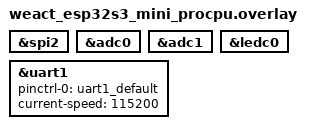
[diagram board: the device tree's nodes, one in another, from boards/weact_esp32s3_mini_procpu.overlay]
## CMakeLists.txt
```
cmake_minimum_required(VERSION 3.28.0)
find_package(Zephyr REQUIRED HINTS $ENV{ZEPHYR_BASE})
project(esp32s3_testbench)
target_sources(app PRIVATE
    src/main.c
    src/shell_cmds.c
    src/gpio_handler.c
    src/adc_handler.c
    src/pwm_handler.c
    src/spi_handler.c
    src/uart_handler.c
)
target_include_directories(app PRIVATE ${CMAKE_CURRENT_SOURCE_DIR}/inc)
```

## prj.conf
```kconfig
CONFIG_GPIO=y
CONFIG_SERIAL=y
CONFIG_CONSOLE=y
CONFIG_PRINTK=y
CONFIG_LOG=y
CONFIG_LOG_DEFAULT_LEVEL=3

# Zephyr shell (command interface over USB Serial/JTAG)
CONFIG_SHELL=y
CONFIG_SHELL_BACKEND_SERIAL=y
CONFIG_SHELL_PROMPT_UART="tb:~$ "

# Peripherals
CONFIG_ADC=y
CONFIG_PWM=y
CONFIG_SPI=y
```

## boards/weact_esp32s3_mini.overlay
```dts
/ {
    aliases {
        /* Logical names used by the command protocol */
    };
};

&gpio0 {
    status = "okay";
};
```

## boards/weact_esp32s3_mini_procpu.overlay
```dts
/* Enable peripherals used by the testbench */
&spi2 {
    status = "okay";
};

&adc0 {
    status = "okay";
};

&adc1 {
    status = "okay";
};

&ledc0 {
    status = "okay";
};

&uart1 {
    status = "okay";
    pinctrl-0 = <&uart1_default>;
    pinctrl-names = "default";
    current-speed = <115200>;
};
```

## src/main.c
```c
/*
 * Copyright (c) 2026 ITI Zephyr Playground
 * SPDX-License-Identifier: Apache-2.0
 */

#include <zephyr/kernel.h>
#include <zephyr/sys/printk.h>

int main(void)
{
    printk("ESP32-S3 Testbench ready (shell on USB Serial/JTAG)\r\n");
    while (1) {
        k_msleep(1000);
    }
    return 0;
}
```

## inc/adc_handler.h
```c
#ifndef ADC_HANDLER_H
#define ADC_HANDLER_H
int adc_handler_read(int channel, int *value);
#endif
```

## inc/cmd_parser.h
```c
#ifndef CMD_PARSER_H
#define CMD_PARSER_H

void cmd_parser_init(void);
void cmd_parser_process(void);

#endif
```

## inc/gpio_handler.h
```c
#ifndef GPIO_HANDLER_H
#define GPIO_HANDLER_H

int gpio_handler_config(int pin, int is_out);
int gpio_handler_set(int pin, int value);
int gpio_handler_get(int pin, int *value);

#endif
```

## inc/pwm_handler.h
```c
#ifndef PWM_HANDLER_H
#define PWM_HANDLER_H
int pwm_handler_set(int channel, int duty_percent);
#endif
```

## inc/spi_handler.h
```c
#ifndef SPI_HANDLER_H
#define SPI_HANDLER_H
int spi_handler_transfer(const unsigned char *tx, unsigned char *rx, size_t len);
#endif
```

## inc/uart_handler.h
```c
#ifndef UART_HANDLER_H
#define UART_HANDLER_H

int uart_handler_send(const char *text);
int uart_handler_recv(char *buf, size_t bufsize);

#endif
```

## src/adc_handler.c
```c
#include <zephyr/kernel.h>
#include <zephyr/device.h>
#include <zephyr/drivers/adc.h>

#include "adc_handler.h"

static const struct device *const adc_dev = DEVICE_DT_GET(DT_NODELABEL(adc0));

int adc_handler_read(int channel, int *value)
{
    if (!device_is_ready(adc_dev)) {
        return -1;
    }

    struct adc_channel_cfg cfg = {
        .gain = ADC_GAIN_1,
        .reference = ADC_REF_INTERNAL,
        .acquisition_time = ADC_ACQ_TIME_DEFAULT,
        .channel_id = channel,
    };

    int err = adc_channel_setup(adc_dev, &cfg);
    if (err < 0) {
        return err;
    }

    int16_t buf = 0;
    struct adc_sequence seq = {
        .channels = BIT(channel),
        .buffer = &buf,
        .buffer_size = sizeof(buf),
        .resolution = 12,
    };

    err = adc_read(adc_dev, &seq);
    if (err < 0) {
        return err;
    }

    *value = buf;
    return 0;
}
```

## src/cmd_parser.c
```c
#include <zephyr/kernel.h>
#include <zephyr/device.h>
#include <zephyr/drivers/uart.h>
#include <string.h>
#include <stdlib.h>
#include <stdio.h>

#include "cmd_parser.h"
#include "gpio_handler.h"
#include "adc_handler.h"
#include "pwm_handler.h"
#include "spi_handler.h"

static const struct device *const uart_dev = DEVICE_DT_GET(DT_CHOSEN(zephyr_console));

static char line_buf[128];
static size_t line_len = 0;

static void uart_send(const char *s)
{
    while (*s) {
        uart_poll_out(uart_dev, *s++);
    }
    uart_poll_out(uart_dev, '\r');
    uart_poll_out(uart_dev, '\n');
}

static void handle_line(char *line)
{
    char cmd[16] = {0}, a[16] = {0}, b[16] = {0};
    int n = sscanf(line, "%15s %15s %15s", cmd, a, b);

    if (!strcmp(line, "ping")) { uart_send("PONG"); return; }
    if (!strcmp(line, "help")) {
        uart_send("Commands: ping, help, gpio config/set/get, adc read <ch>, pwm set <ch> <duty>, spi xfer <hex...>");
        return;
    }

    if (!strcmp(cmd, "gpio")) {
        if (!strcmp(a, "config") ) {
            int pin; char mode[8];
            if (sscanf(line, "gpio config %d %7s", &pin, mode) == 2) {
                int r = gpio_handler_config(pin, !strcmp(mode, "out"));
                uart_send(r == 0 ? "OK" : "ERR 2");
                return;
            }
        }
        if (!strcmp(a, "set")) {
            int pin, val;
            if (sscanf(line, "gpio set %d %d", &pin, &val) == 2) {
                int r = gpio_handler_set(pin, val);
                uart_send(r == 0 ? "OK" : "ERR 2");
                return;
            }
        }
        if (!strcmp(a, "get")) {
            int pin;
            if (sscanf(line, "gpio get %d", &pin) == 1) {
                int v = 0;
                int r = gpio_handler_get(pin, &v);
                if (r == 0) {
                    char resp[32];
                    snprintf(resp, sizeof(resp), "VAL %d", v);
                    uart_send(resp);
                } else {
                    uart_send("ERR 2");
                }
                return;
            }
        }
    }

    if (!strcmp(cmd, "adc")) {
        if (!strcmp(a, "read")) {
            int ch;
            if (sscanf(line, "adc read %d", &ch) == 1) {
                int v = 0;
                int r = adc_handler_read(ch, &v);
                if (r == 0) {
                    char resp[32];
                    snprintf(resp, sizeof(resp), "VAL %d", v);
                    uart_send(resp);
                } else {
                    uart_send("ERR 2");
                }
                return;
            }
        }
    }

    if (!strcmp(cmd, "pwm")) {
        if (!strcmp(a, "set")) {
            int ch, duty;
            if (sscanf(line, "pwm set %d %d", &ch, &duty) == 2) {
                int r = pwm_handler_set(ch, duty);
                uart_send(r == 0 ? "OK" : "ERR 2");
                return;
            }
        }
    }

    if (!strcmp(cmd, "spi")) {
        if (!strcmp(a, "xfer")) {
            /* parse hex bytes after "spi xfer" */
            unsigned char tx[16], rx[16];
            size_t len = 0;
            char *p = line + strlen("spi xfer");
            while (*p && len < sizeof(tx)) {
                while (*p == ' ') p++;
                if (!*p) break;
                unsigned int byte;
                if (sscanf(p, "%2x", &byte) == 1) {
                    tx[len] = (unsigned char)byte;
                    rx[len] = 0;
                    len++;
                    p += 2;
                } else {
                    break;
                }
            }
            if (len > 0) {
                int r = spi_handler_transfer(tx, rx, len);
                if (r == 0) {
                    char resp[64];
                    size_t off = 0;
                    off += snprintf(resp + off, sizeof(resp) - off, "RX");
                    for (size_t i = 0; i < len; i++) {
                        off += snprintf(resp + off, sizeof(resp) - off, " %02X", rx[i]);
                    }
                    uart_send(resp);
                } else {
                    uart_send("ERR 2");
                }
                return;
            }
        }
    }

    uart_send("ERR 1");
}

void cmd_parser_init(void)
{
    if (!device_is_ready(uart_dev)) {
        return;
    }
}

void cmd_parser_process(void)
{
    unsigned char c;
    int ret = uart_poll_in(uart_dev, &c);
    if (ret == 0) {
        if (c == '\r' || c == '\n') {
            if (line_len > 0) {
                line_buf[line_len] = '\0';
                handle_line(line_buf);
                line_len = 0;
            }
        } else if (line_len < sizeof(line_buf) - 1) {
            line_buf[line_len++] = (char)c;
        }
    }
}
```

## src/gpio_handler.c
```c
#include <zephyr/kernel.h>
#include <zephyr/device.h>
#include <zephyr/drivers/gpio.h>

#include "gpio_handler.h"

static const struct device *const gpio_dev = DEVICE_DT_GET(DT_NODELABEL(gpio0));

int gpio_handler_config(int pin, int is_out)
{
    gpio_flags_t flags = is_out ? GPIO_OUTPUT_INACTIVE : GPIO_INPUT;
    return gpio_pin_configure(gpio_dev, pin, flags);
}

int gpio_handler_set(int pin, int value)
{
    return gpio_pin_set(gpio_dev, pin, value);
}

int gpio_handler_get(int pin, int *value)
{
    int v = gpio_pin_get(gpio_dev, pin);
    if (v < 0) {
        return v;
    }
    *value = v;
    return 0;
}
```

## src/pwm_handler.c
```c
#include <zephyr/kernel.h>
#include <zephyr/device.h>
#include <zephyr/drivers/pwm.h>

#include "pwm_handler.h"

static const struct device *const pwm_dev = DEVICE_DT_GET(DT_NODELABEL(ledc0));

int pwm_handler_set(int channel, int duty_percent)
{
    if (!device_is_ready(pwm_dev)) {
        return -1;
    }
    if (duty_percent < 0) duty_percent = 0;
    if (duty_percent > 100) duty_percent = 100;

    /* period = 1 MHz clock / 1000 = 1 kHz PWM; pulse = duty% of period */
    uint32_t period = 1000000; /* cycles */
    uint32_t pulse = (period * duty_percent) / 100;

    return pwm_set_cycles(pwm_dev, channel, period, pulse, 0);
}
```

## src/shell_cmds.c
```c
#include <zephyr/kernel.h>
#include <zephyr/shell/shell.h>
#include <stdlib.h>
#include <stdio.h>

#include "gpio_handler.h"
#include "adc_handler.h"
#include "pwm_handler.h"
#include "spi_handler.h"
#include "uart_handler.h"

static int cmd_ping(const struct shell *sh, size_t argc, char **argv)
{
    shell_print(sh, "PONG");
    return 0;
}

static int cmd_hello(const struct shell *sh, size_t argc, char **argv)
{
    shell_print(sh, "Hello from ESP32-S3!");
    return 0;
}

static int cmd_gpio(const struct shell *sh, size_t argc, char **argv)
{
    if (argc < 2) {
        shell_error(sh, "usage: gpio <config|set|get> ...");
        return -EINVAL;
    }
    if (!strcmp(argv[1], "config") && argc == 4) {
        int pin = atoi(argv[2]);
        int is_out = !strcmp(argv[3], "out");
        int r = gpio_handler_config(pin, is_out);
        shell_print(sh, r == 0 ? "OK" : "ERR %d", r);
        return 0;
    }
    if (!strcmp(argv[1], "set") && argc == 4) {
        int pin = atoi(argv[2]);
        int val = atoi(argv[3]);
        int r = gpio_handler_set(pin, val);
        shell_print(sh, r == 0 ? "OK" : "ERR %d", r);
        return 0;
    }
    if (!strcmp(argv[1], "get") && argc == 3) {
        int pin = atoi(argv[2]);
        int v = 0;
        int r = gpio_handler_get(pin, &v);
        if (r == 0) {
            shell_print(sh, "VAL %d", v);
        } else {
            shell_print(sh, "ERR %d", r);
        }
        return 0;
    }
    shell_error(sh, "bad gpio command");
    return -EINVAL;
}

static int cmd_adc(const struct shell *sh, size_t argc, char **argv)
{
    if (argc == 3 && !strcmp(argv[1], "read")) {
        int ch = atoi(argv[2]);
        int v = 0;
        int r = adc_handler_read(ch, &v);
        if (r == 0) {
            shell_print(sh, "VAL %d", v);
        } else {
            shell_print(sh, "ERR %d", r);
        }
        return 0;
    }
    shell_error(sh, "usage: adc read <ch>");
    return -EINVAL;
}

static int cmd_pwm(const struct shell *sh, size_t argc, char **argv)
{
    if (argc == 4 && !strcmp(argv[1], "set")) {
        int ch = atoi(argv[2]);
        int duty = atoi(argv[3]);
        int r = pwm_handler_set(ch, duty);
        shell_print(sh, r == 0 ? "OK" : "ERR %d", r);
        return 0;
    }
    shell_error(sh, "usage: pwm set <ch> <0-100>");
    return -EINVAL;
}

static int cmd_spi(const struct shell *sh, size_t argc, char **argv)
{
    if (argc >= 3 && !strcmp(argv[1], "xfer")) {
        unsigned char tx[16], rx[16];
        size_t len = 0;
        for (size_t i = 2; i < argc && len < sizeof(tx); i++) {
            tx[len] = (unsigned char)strtoul(argv[i], NULL, 16);
            rx[len] = 0;
            len++;
        }
        int r = spi_handler_transfer(tx, rx, len);
        if (r == 0) {
            shell_fprintf(sh, SHELL_NORMAL, "RX");
            for (size_t i = 0; i < len; i++) {
                shell_fprintf(sh, SHELL_NORMAL, " %02X", rx[i]);
            }
            shell_fprintf(sh, SHELL_NORMAL, "\n");
        } else {
            shell_print(sh, "ERR %d", r);
        }
        return 0;
    }
    shell_error(sh, "usage: spi xfer <hex...>");
    return -EINVAL;
}


static int cmd_uart(const struct shell *sh, size_t argc, char **argv)
{
    if (argc >= 3 && !strcmp(argv[1], "send")) {
        /* join argv[2..] into one string */
        char buf[128];
        size_t off = 0;
        for (size_t i = 2; i < argc && off < sizeof(buf) - 1; i++) {
            if (i > 2 && off < sizeof(buf) - 1) buf[off++] = ' ';
            size_t l = strlen(argv[i]);
            if (off + l >= sizeof(buf)) l = sizeof(buf) - off - 1;
            memcpy(buf + off, argv[i], l);
            off += l;
        }
        buf[off] = '\0';
        int r = uart_handler_send(buf);
        shell_print(sh, r == 0 ? "OK" : "ERR %d", r);
        return 0;
    }
    if (argc == 2 && !strcmp(argv[1], "recv")) {
        char buf[128];
        int n = uart_handler_recv(buf, sizeof(buf));
        if (n >= 0) {
            shell_print(sh, "RX %s", buf);
        } else {
            shell_print(sh, "ERR %d", n);
        }
        return 0;
    }
    shell_error(sh, "usage: uart send <text...> | uart recv");
    return -EINVAL;
}

SHELL_CMD_REGISTER(ping, NULL, "Liveness check", cmd_ping);
SHELL_CMD_REGISTER(hello, NULL, "Hello message", cmd_hello);
SHELL_CMD_REGISTER(gpio, NULL, "GPIO: config/set/get", cmd_gpio);
SHELL_CMD_REGISTER(adc, NULL, "ADC: read <ch>", cmd_adc);
SHELL_CMD_REGISTER(pwm, NULL, "PWM: set <ch> <0-100>", cmd_pwm);
SHELL_CMD_REGISTER(spi, NULL, "SPI: xfer <hex...>", cmd_spi);
SHELL_CMD_REGISTER(uart, NULL, "UART1: send/recv", cmd_uart);
```

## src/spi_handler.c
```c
#include <zephyr/kernel.h>
#include <zephyr/device.h>
#include <zephyr/drivers/spi.h>

#include "spi_handler.h"

static const struct device *const spi_dev = DEVICE_DT_GET(DT_NODELABEL(spi2));

int spi_handler_transfer(const unsigned char *tx, unsigned char *rx, size_t len)
{
    if (!device_is_ready(spi_dev)) {
        return -1;
    }

    struct spi_config config = {
        .frequency = 1000000,
        .operation = SPI_WORD_SET(8) | SPI_TRANSFER_MSB,
        .slave = 0,
        .cs = NULL,
    };

    struct spi_buf tx_buf = { .buf = (void *)tx, .len = len };
    struct spi_buf_set tx_set = { .buffers = &tx_buf, .count = 1 };

    struct spi_buf rx_buf = { .buf = rx, .len = len };
    struct spi_buf_set rx_set = { .buffers = &rx_buf, .count = 1 };

    return spi_transceive(spi_dev, &config, &tx_set, &rx_set);
}
```
